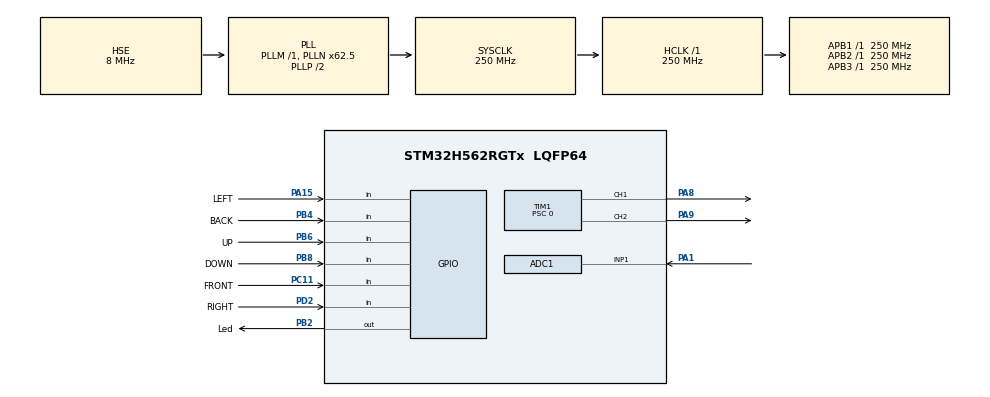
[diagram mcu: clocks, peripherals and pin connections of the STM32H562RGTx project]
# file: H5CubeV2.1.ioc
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ADC1.Channel-0\#ChannelRegularConversion=ADC_CHANNEL_1
ADC1.ClockPrescaler=ADC_CLOCK_ASYNC_DIV6
ADC1.DMAContinuousRequests=ENABLE
ADC1.ExternalTrigConv=ADC_EXTERNALTRIG_T2_TRGO
ADC1.NbrOfConversion=1
ADC1.NbrOfConversionFlag=1
ADC1.OversamplingMode=ENABLE
ADC1.Ratio=ADC_OVERSAMPLING_RATIO_4
ADC1.SamplingTime-0\#ChannelRegularConversion=ADC_SAMPLETIME_12CYCLES_5
ADC1.master=1
BOOTPATH.BootPathName=LEGACY
BOOTPATH.UserSelectedBootPath=LEGACY
CORTEX_M33_NS.Number-Cortex_Memory_Protection_Unit_Region0_OTP_RO_AREAS_Settings=MPU_REGION_NUMBER0
CORTEX_M33_NS.default_mode_Activation=1
CORTEX_M33_NS.userName=CORTEX_M33
GPDMA1.CIRCULARMODE_GPDMACH5=ENABLE
GPDMA1.CIRCULARMODE_GPDMACH7=DISABLE
GPDMA1.DESTDATAWIDTH_GPDMACH5=DMA_DEST_DATAWIDTH_HALFWORD
GPDMA1.DESTDATAWIDTH_GPDMACH6=DMA_DEST_DATAWIDTH_WORD
GPDMA1.DESTDATAWIDTH_GPDMACH7=DMA_DEST_DATAWIDTH_WORD
GPDMA1.DESTINC_GPDMACH5=DMA_DINC_INCREMENTED
GPDMA1.DIRECTION_GPDMACH6=DMA_MEMORY_TO_PERIPH
GPDMA1.DIRECTION_GPDMACH7=DMA_MEMORY_TO_PERIPH
GPDMA1.IPHANDLE_GPDMACH5-SIMPLEREQUEST_GPDMACH5=__NULL
GPDMA1.IPHANDLE_GPDMACH6-SIMPLEREQUEST_GPDMACH6=__NULL
GPDMA1.IPHANDLE_GPDMACH7-SIMPLEREQUEST_GPDMACH7=__NULL
GPDMA1.REQUEST_GPDMACH5=GPDMA1_REQUEST_ADC1
GPDMA1.REQUEST_GPDMACH6=GPDMA1_REQUEST_TIM1_CH2
GPDMA1.REQUEST_GPDMACH7=GPDMA1_REQUEST_TIM1_CH1
GPDMA1.SRCDATAWIDTH_GPDMACH5=DMA_SRC_DATAWIDTH_HALFWORD
GPDMA1.SRCDATAWIDTH_GPDMACH7=DMA_SRC_DATAWIDTH_BYTE
GPDMA1.SRCINC_GPDMACH6=DMA_SINC_INCREMENTED
GPDMA1.SRCINC_GPDMACH7=DMA_SINC_INCREMENTED
Linkedlist.MDMA_Channel0.GP_SW.0.BlkHWRequest=DMA_BREQ_SINGLE_BURST
Linkedlist.MDMA_Channel0.GP_SW.0.DataHandling=NONE
Linkedlist.MDMA_Channel0.GP_SW.0.DataSize=2
Linkedlist.MDMA_Channel0.GP_SW.0.DestBurstLength=1
Linkedlist.MDMA_Channel0.GP_SW.0.DestDataWidth=DMA_DEST_DATAWIDTH_HALFWORD
Linkedlist.MDMA_Channel0.GP_SW.0.DestInc=DMA_DINC_FIXED
Linkedlist.MDMA_Channel0.GP_SW.0.Direction=DMA_MEMORY_TO_PERIPH
Linkedlist.MDMA_Channel0.GP_SW.0.DstAddress=0
Linkedlist.MDMA_Channel0.GP_SW.0.Instance=MDMA_Channel0
Linkedlist.MDMA_Channel0.GP_SW.0.LL_CIRCULARNODE=Node
Linkedlist.MDMA_Channel0.GP_SW.0.LL_MASTERDMA=GPDMA1
Linkedlist.MDMA_Channel0.GP_SW.0.LL_NAME=TIMQueue
Linkedlist.MDMA_Channel0.GP_SW.0.LL_TYPE=CIRCULAR
Linkedlist.MDMA_Channel0.GP_SW.0.Mode=DMA_NORMAL
Linkedlist.MDMA_Channel0.GP_SW.0.NODE_NAME=Node
Linkedlist.MDMA_Channel0.GP_SW.0.Requestforcodegen=GPDMA1_REQUEST_TIM1_CH1
Linkedlist.MDMA_Channel0.GP_SW.0.SrcAddress=0
Linkedlist.MDMA_Channel0.GP_SW.0.SrcBurstLength=1
Linkedlist.MDMA_Channel0.GP_SW.0.SrcDataWidth=DMA_SRC_DATAWIDTH_HALFWORD
Linkedlist.MDMA_Channel0.GP_SW.0.SrcInc=DMA_SINC_FIXED
Linkedlist.MDMA_Channel0.GP_SW.0.TransferAllocatedPortSrc=DMA_SRC_ALLOCATED_PORT0
Linkedlist.MDMA_Channel0.GP_SW.0.TransferEventMode=DMA_TCEM_BLOCK_TRANSFER
Linkedlist.MDMA_Channel0.GP_SW.0.TriggerPolarity=DMA_TRIG_POLARITY_MASKED
Linkedlist.MDMA_Channel0.Request0=GP_SW
Linkedlist.MDMA_Channel0.RequestsNb=1
Linkedlist.RequestSet0=MDMA_Channel0
Linkedlist.RequestSetsNb=1
Mcu.Family=STM32H5
Mcu.Name=STM32H562RGTx
Mcu.Package=LQFP64
NVIC.GPDMA1_Channel5_IRQn=true\:0\:0\:false\:false\:true\:false\:true\:true
NVIC.GPDMA1_Channel6_IRQn=true\:0\:0\:false\:false\:true\:false\:true\:true
NVIC.GPDMA1_Channel7_IRQn=true\:0\:0\:false\:false\:true\:false\:true\:true
NVIC.PriorityGroup=NVIC_PRIORITYGROUP_4
PA1.Signal=ADCx_INP1
PA13(JTMS/SWDIO).Mode=Serial_Wire
PA13(JTMS/SWDIO).Signal=DEBUG_JTMS-SWDIO
PA14(JTCK/SWCLK).Mode=Serial_Wire
PA14(JTCK/SWCLK).Signal=DEBUG_JTCK-SWCLK
PA15(JTDI).GPIO_Label=LEFT
PA15(JTDI).GPIO_PuPd=GPIO_PULLUP
PA15(JTDI).Signal=GPIO_Input
PA8.Signal=S_TIM1_CH1
PA9.Signal=S_TIM1_CH2
PB2.GPIO_Label=Led
PB2.Signal=GPIO_Output
PB4(NJTRST).GPIO_Label=BACK
PB4(NJTRST).GPIO_PuPd=GPIO_PULLUP
PB4(NJTRST).Signal=GPIO_Input
PB6.GPIO_Label=UP
PB6.GPIO_PuPd=GPIO_PULLUP
PB6.Signal=GPIO_Input
PB8.GPIO_Label=DOWN
PB8.GPIO_PuPd=GPIO_PULLUP
PB8.Signal=GPIO_Input
PC11.GPIO_Label=FRONT
PC11.GPIO_PuPd=GPIO_PULLUP
PC11.Signal=GPIO_Input
PD2.GPIO_Label=RIGHT
PD2.GPIO_PuPd=GPIO_PULLUP
PD2.Signal=GPIO_Input
PH0-OSC_IN(PH0).Mode=HSE-External-Oscillator
PH0-OSC_IN(PH0).Signal=RCC_OSC_IN
PH1-OSC_OUT(PH1).Mode=HSE-External-Oscillator
PH1-OSC_OUT(PH1).Signal=RCC_OSC_OUT
ProjectManager.HeapSize=0x6000
ProjectManager.StackSize=0x400
ProjectManager.TargetToolchain=CMake
RCC.ADCFreq_Value=250000000
RCC.AHBFreq_Value=250000000
RCC.APB1Freq_Value=250000000
RCC.APB1TimFreq_Value=250000000
RCC.APB2Freq_Value=250000000
RCC.APB2TimFreq_Value=250000000
RCC.APB3Freq_Value=250000000
RCC.CSI_VALUE=4000000
RCC.CortexFreq_Value=250000000
RCC.EPOD_VALUE=8000000
RCC.HCLKFreq_Value=250000000
RCC.HSE_VALUE=8000000
RCC.HSI48_VALUE=48000000
RCC.HSI_VALUE=64000000
RCC.LSE_VALUE=32768
RCC.LSIRC_VALUE=32000
RCC.PLL2FRACN=0
RCC.PLL3FRACN=0
RCC.PLLFRACN=4096
RCC.PLLN=62
RCC.PLLSourceVirtual=RCC_PLL1_SOURCE_HSE
RCC.SYSCLKFreq_VALUE=250000000
RCC.SYSCLKSource=RCC_SYSCLKSOURCE_PLLCLK
RCC.USBFreq_Value=48000000
RCC.VCOOutputFreq_Value=500000000
SH.ADCx_INP1.0=ADC1_INP1,IN1-Single-Ended
SH.S_TIM1_CH1.0=TIM1_CH1,PWM Generation1 CH1
SH.S_TIM1_CH2.0=TIM1_CH2,PWM Generation2 CH2
TIM1.AutoReloadPreload=TIM_AUTORELOAD_PRELOAD_ENABLE
TIM1.Channel-PWM\ Generation1\ CH1=TIM_CHANNEL_1
TIM1.Channel-PWM\ Generation2\ CH2=TIM_CHANNEL_2
TIM1.Dithering=Disable
TIM1.OC1Preload_PWM=ENABLE
TIM1.PeriodNoDither=311
TIM1.Prescaler=0
TIM1.PulseNoDither_1=10
TIM1.PulseNoDither_2=10
TIM2.Channel-Output\ Compare1\ No\ Output=TIM_CHANNEL_1
TIM2.PeriodNoDither=25
TIM2.Prescaler=249
TIM2.TIM_MasterOutputTrigger=TIM_TRGO_UPDATE
TIM2.TIM_MasterSlaveMode=TIM_MASTERSLAVEMODE_DISABLE
VP_BOOTPATH_VS_BOOTPATH.Mode=BP_Activate
VP_CORTEX_M33_NS_VS_Hclk.Mode=Hclk_Mode
VP_GPDMA1_VS_GPDMACH5.Mode=SIMPLEREQUEST_GPDMACH5
VP_GPDMA1_VS_GPDMACH6.Mode=SIMPLEREQUEST_GPDMACH6
VP_GPDMA1_VS_GPDMACH7.Mode=SIMPLEREQUEST_GPDMACH7
VP_ICACHE_VS_ICACHE.Mode=DirectMappedCache
VP_MEMORYMAP_VS_MEMORYMAP.Mode=CurAppReg
VP_PWR_VS_LPOM.Mode=PowerOptimisation
VP_PWR_VS_SECSignals.Mode=Security/Privilege
VP_TIM2_VS_no_output1.Mode=Output Compare1 No Output
board=custom

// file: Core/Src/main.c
/* USER CODE BEGIN Header */
/**
  ******************************************************************************
  * @file           : main.c
  * @brief          : Main program body
  ******************************************************************************
  * @attention
  *
  * Copyright (c) 2026 STMicroelectronics.
  * All rights reserved.
  *
  * This software is licensed under terms that can be found in the LICENSE file
  * in the root directory of this software component.
  * If no LICENSE file comes with this software, it is provided AS-IS.
  *
  ******************************************************************************
  */
/* USER CODE END Header */
#include "main.h"
#include "adc.h"
#include "gpdma.h"
#include "icache.h"
#include "tim.h"
#include "gpio.h"

/* USER CODE BEGIN Includes */
#include "stm32h5xx_hal.h"
#include "core_cm33.h"
#include "stdlib.h"
#include "WS2812B/Led.h"
#include <stdbool.h>
#include "microfone.h"

/* USER CODE END Includes */

void SystemClock_Config(void);
static void MPU_Config(void);

int main(void)
{

  /* MCU Configuration--------------------------------------------------------*/

  /* MPU Configuration--------------------------------------------------------*/
  MPU_Config();

  /* Reset of all peripherals, Initializes the Flash interface and the Systick. */
  HAL_Init();

  /* Configure the system clock */
  SystemClock_Config();

  /* Initialize all configured peripherals */
  MX_GPIO_Init();
  MX_GPDMA1_Init();
  MX_ICACHE_Init();
  MX_TIM1_Init();
  MX_ADC1_Init();
  MX_TIM2_Init();
  /* USER CODE BEGIN 2 */

  Microfone_Init(&htim2, &hadc1);
  WS2812B_Init(&htim1, TIM_CHANNEL_1, &htim1, TIM_CHANNEL_2);

  /* USER CODE END 2 */

  /* Infinite loop */
  while (1)
  {

    /* USER CODE BEGIN 3 */

    HAL_Delay(1000);

    HAL_GPIO_TogglePin(Led_GPIO_Port, Led_Pin);
  }
  /* USER CODE END 3 */
}

void SystemClock_Config(void)
{
  RCC_OscInitTypeDef RCC_OscInitStruct = {0};
  RCC_ClkInitTypeDef RCC_ClkInitStruct = {0};

  /** Configure the main internal regulator output voltage
  */
  __HAL_PWR_VOLTAGESCALING_CONFIG(PWR_REGULATOR_VOLTAGE_SCALE0);

  while(!__HAL_PWR_GET_FLAG(PWR_FLAG_VOSRDY)) {}

  /** Initializes the RCC Oscillators according to the specified parameters
  * in the RCC_OscInitTypeDef structure.
  */
  RCC_OscInitStruct.OscillatorType = RCC_OSCILLATORTYPE_HSE;
  RCC_OscInitStruct.HSEState = RCC_HSE_ON;
  RCC_OscInitStruct.PLL.PLLState = RCC_PLL_ON;
  RCC_OscInitStruct.PLL.PLLSource = RCC_PLL1_SOURCE_HSE;
  RCC_OscInitStruct.PLL.PLLM = 1;
  RCC_OscInitStruct.PLL.PLLN = 62;
  RCC_OscInitStruct.PLL.PLLP = 2;
  RCC_OscInitStruct.PLL.PLLQ = 2;
  RCC_OscInitStruct.PLL.PLLR = 2;
  RCC_OscInitStruct.PLL.PLLRGE = RCC_PLL1_VCIRANGE_3;
  RCC_OscInitStruct.PLL.PLLVCOSEL = RCC_PLL1_VCORANGE_WIDE;
  RCC_OscInitStruct.PLL.PLLFRACN = 4096;
  if (HAL_RCC_OscConfig(&RCC_OscInitStruct) != HAL_OK)
  {
    Error_Handler();
  }

  /** Initializes the CPU, AHB and APB buses clocks
  */
  RCC_ClkInitStruct.ClockType = RCC_CLOCKTYPE_HCLK|RCC_CLOCKTYPE_SYSCLK
                              |RCC_CLOCKTYPE_PCLK1|RCC_CLOCKTYPE_PCLK2
                              |RCC_CLOCKTYPE_PCLK3;
  RCC_ClkInitStruct.SYSCLKSource = RCC_SYSCLKSOURCE_PLLCLK;
  RCC_ClkInitStruct.AHBCLKDivider = RCC_SYSCLK_DIV1;
  RCC_ClkInitStruct.APB1CLKDivider = RCC_HCLK_DIV1;
  RCC_ClkInitStruct.APB2CLKDivider = RCC_HCLK_DIV1;
  RCC_ClkInitStruct.APB3CLKDivider = RCC_HCLK_DIV1;

  if (HAL_RCC_ClockConfig(&RCC_ClkInitStruct, FLASH_LATENCY_5) != HAL_OK)
  {
    Error_Handler();
  }

  /** Configure the programming delay
  */
  __HAL_FLASH_SET_PROGRAM_DELAY(FLASH_PROGRAMMING_DELAY_2);
}

 /* MPU Configuration */

void MPU_Config(void)
{
  MPU_Region_InitTypeDef MPU_InitStruct = {0};
  MPU_Attributes_InitTypeDef MPU_AttributesInit = {0};

  /* Disables the MPU */
  HAL_MPU_Disable();

  /** Initializes and configures the Region 0 and the memory to be protected
  */
  MPU_InitStruct.Enable = MPU_REGION_ENABLE;
  MPU_InitStruct.Number = MPU_REGION_NUMBER0;
  MPU_InitStruct.BaseAddress = 0x08FFF000;
  MPU_InitStruct.LimitAddress = 0x08FFFFFF;
  MPU_InitStruct.AttributesIndex = MPU_ATTRIBUTES_NUMBER0;
  MPU_InitStruct.AccessPermission = MPU_REGION_ALL_RO;
  MPU_InitStruct.DisableExec = MPU_INSTRUCTION_ACCESS_DISABLE;
  MPU_InitStruct.IsShareable = MPU_ACCESS_NOT_SHAREABLE;

  HAL_MPU_ConfigRegion(&MPU_InitStruct);

  /** Initializes and configures the Attribute 0 and the memory to be protected
  */
  MPU_AttributesInit.Number = MPU_ATTRIBUTES_NUMBER0;
  MPU_AttributesInit.Attributes = INNER_OUTER(MPU_NOT_CACHEABLE);

  HAL_MPU_ConfigMemoryAttributes(&MPU_AttributesInit);
  /* Enables the MPU */
  HAL_MPU_Enable(MPU_PRIVILEGED_DEFAULT);

}

void Error_Handler(void)
{
  /* USER CODE BEGIN Error_Handler_Debug */
  /* User can add his own implementation to report the HAL error return state */
  __disable_irq();
  while (1)
  {
    HAL_Delay(100);
    HAL_GPIO_TogglePin(Led_GPIO_Port, Led_Pin);
  }
  /* USER CODE END Error_Handler_Debug */
}
